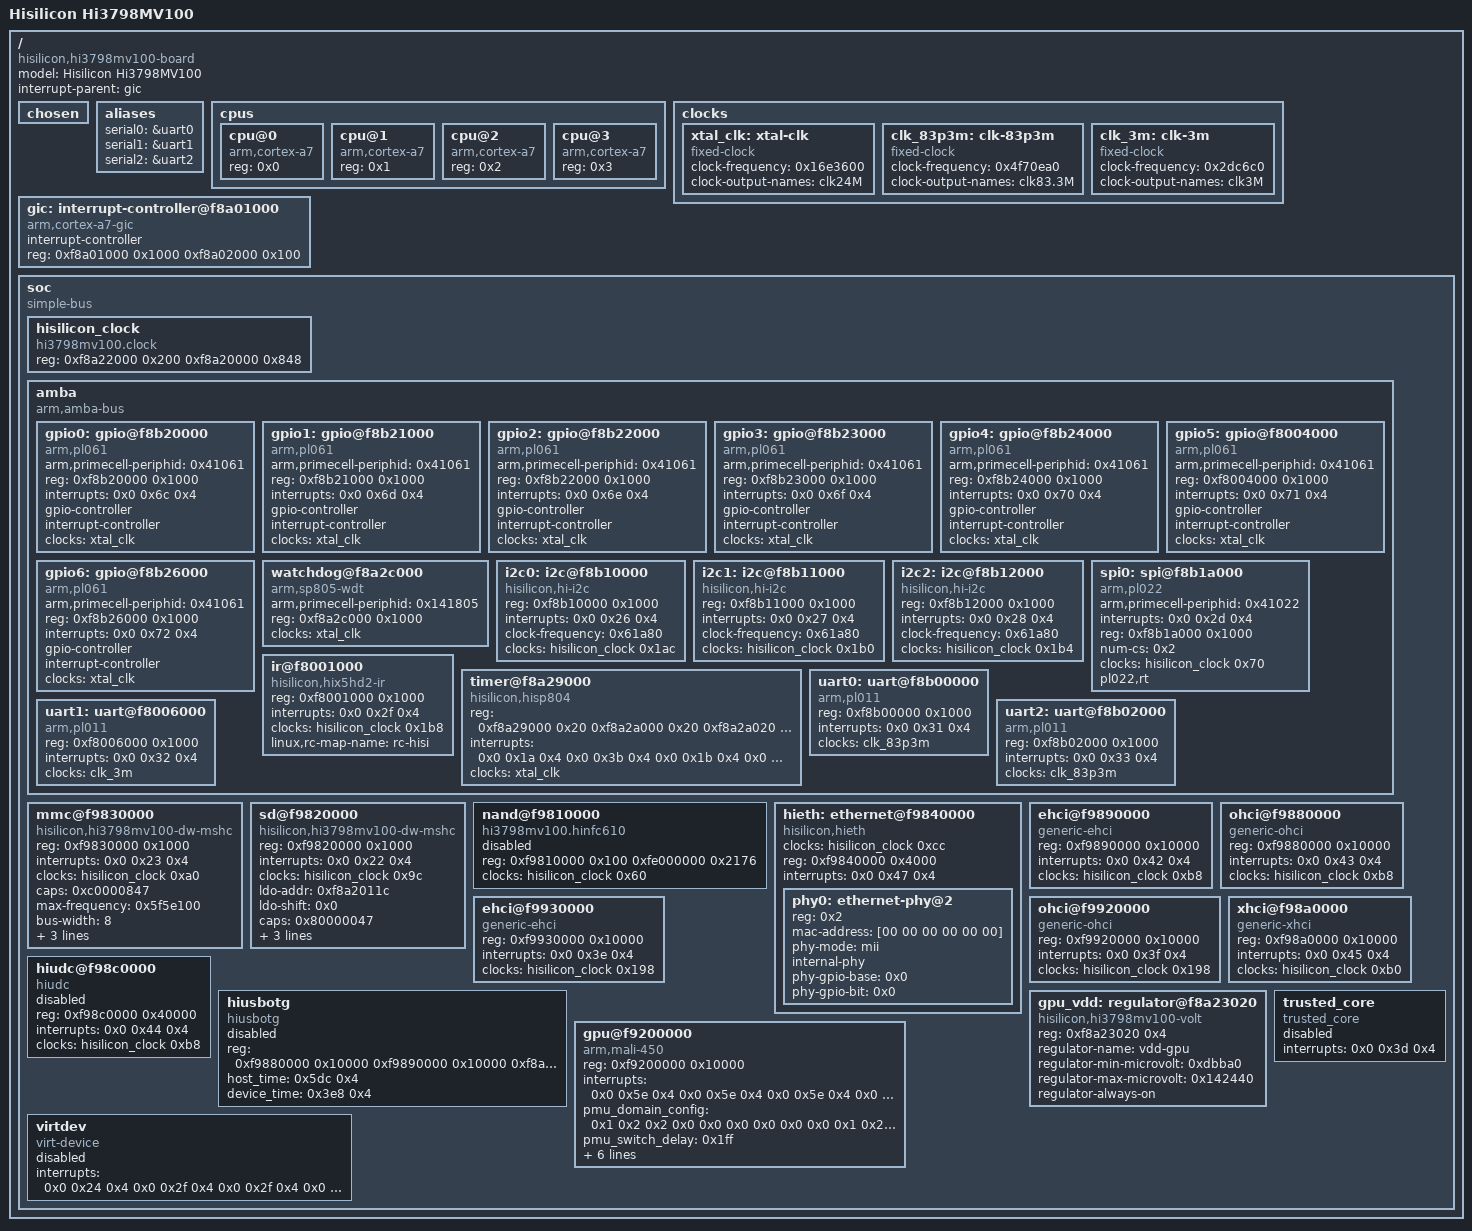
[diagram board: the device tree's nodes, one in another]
// SPDX-License-Identifier: GPL-2.0
/*
 * Device Tree for Hi3798MV100-based board
 *
 * Base: vendor DTB extracted from hi_kernel.bin (working vendor kernel)
 * All hardware addresses, IRQs, clock offsets and properties are taken
 * directly from the vendor DTB — these are confirmed correct for this board.
 *
 * Changes made for mainline kernel compilation:
 *  - Removed 0x prefix from all node @ unit addresses (dtc requirement)
 *  - Removed dots from node names (himciv200.MMC -> mmc, etc.)
 *  - Fixed soc ranges property
 *  - Replaced linux,phandle with phandle only
 *  - MMC/SD: added mainline compatible strings alongside vendor string
 *  - Clock controller: kept vendor compatible as fallback for raw offset clocks
 *  - Nodes with no mainline driver: trusted_core, virtdev, hiudc, hiusbotg
 *    are kept but marked status = "disabled" so they compile but don't probe
 *  - NAND: disabled, no mainline driver exists
 *  - chosen: emptied, U-Boot passes bootargs from its environment
 *  - Added #include for appended DTB support (no clock macros used —
 *    all clock references use the raw phandle+offset form from vendor DTB)
 */

/dts-v1/;

/ {
	model = "Hisilicon Hi3798MV100";
	compatible = "hisilicon,hi3798mv100-board", "hi3798mv100-series";
	#address-cells = <0x1>;
	#size-cells = <0x1>;
	interrupt-parent = <&gic>;

	/* Intentionally empty — U-Boot passes bootargs from its environment.
	 * CONFIG_ARM_ATAG_DTB_COMPAT_CMDLINE_FROM_BOOTLOADER=y handles this. */
	chosen {};

	aliases {
		serial0 = &uart0;
		serial1 = &uart1;
		serial2 = &uart2;
	};

	cpus {
		#address-cells = <0x1>;
		#size-cells = <0x0>;
		cpu@0 {
			device_type = "cpu";
			compatible = "arm,cortex-a7";
			reg = <0x0>;
		};
		cpu@1 {
			device_type = "cpu";
			compatible = "arm,cortex-a7";
			reg = <0x1>;
		};
		cpu@2 {
			device_type = "cpu";
			compatible = "arm,cortex-a7";
			reg = <0x2>;
		};
		cpu@3 {
			device_type = "cpu";
			compatible = "arm,cortex-a7";
			reg = <0x3>;
		};
	};

	/* Fixed clocks — values taken directly from vendor DTB */
	clocks {
		xtal_clk: xtal-clk {
			compatible = "fixed-clock";
			#clock-cells = <0x0>;
			clock-frequency = <0x16e3600>;    /* 24MHz */
			clock-output-names = "clk24M";
			phandle = <0x2>;
		};
		clk_83p3m: clk-83p3m {
			compatible = "fixed-clock";
			#clock-cells = <0x0>;
			clock-frequency = <0x4f70ea0>;    /* 83.3MHz */
			clock-output-names = "clk83.3M";
			phandle = <0x4>;
		};
		clk_3m: clk-3m {
			compatible = "fixed-clock";
			#clock-cells = <0x0>;
			clock-frequency = <0x2dc6c0>;     /* 3MHz */
			clock-output-names = "clk3M";
			phandle = <0x5>;
		};
	};

	/* GIC — addresses from vendor DTB */
	gic: interrupt-controller@f8a01000 {
		compatible = "arm,cortex-a7-gic";
		#interrupt-cells = <0x3>;
		#address-cells = <0x0>;
		interrupt-controller;
		reg = <0xf8a01000 0x1000 0xf8a02000 0x100>;
		phandle = <0x1>;
	};

	soc {
		#address-cells = <0x1>;
		#size-cells = <0x1>;
		compatible = "simple-bus";
		/* FIX: vendor had ranges = <0x0 0x0 0xffffffff> which is wrong.
		 * Empty ranges means 1:1 mapping of child to parent addresses. */
		ranges;

		/* Clock controller.
		 * Kept with vendor compatible "hi3798mv100.clock" because all
		 * peripheral clock references in this DTS use raw register offsets
		 * (<0x3 0xNN>) which only the vendor clock driver understands.
		 * The mainline hisilicon,hi3798mv100-crg driver uses index-based
		 * clock IDs from histb-clock.h which are different. Using the vendor
		 * compatible here means clocks work exactly as they did in the
		 * vendor kernel. If/when the mainline CRG driver gains MV100 support
		 * with matching clock IDs, this can be updated. */
		hisilicon_clock: hisilicon_clock {
			compatible = "hi3798mv100.clock";
			reg = <0xf8a22000 0x200 0xf8a20000 0x848>;
			#clock-cells = <0x1>;
			phandle = <0x3>;
		};

		amba {
			compatible = "arm,amba-bus";
			#address-cells = <0x1>;
			#size-cells = <0x1>;
			ranges;

			/* GPIO — no @ address in vendor DTB, added for mainline */
			gpio0: gpio@f8b20000 {
				compatible = "arm,pl061", "arm,primecell";
				arm,primecell-periphid = <0x41061>;
				reg = <0xf8b20000 0x1000>;
				interrupts = <0x0 0x6c 0x4>;
				gpio-controller;
				#gpio-cells = <0x2>;
				interrupt-controller;
				#interrupt-cells = <0x2>;
				clocks = <&xtal_clk>;
				clock-names = "apb_pclk";
			};
			gpio1: gpio@f8b21000 {
				compatible = "arm,pl061", "arm,primecell";
				arm,primecell-periphid = <0x41061>;
				reg = <0xf8b21000 0x1000>;
				interrupts = <0x0 0x6d 0x4>;
				gpio-controller;
				#gpio-cells = <0x2>;
				interrupt-controller;
				#interrupt-cells = <0x2>;
				clocks = <&xtal_clk>;
				clock-names = "apb_pclk";
			};
			gpio2: gpio@f8b22000 {
				compatible = "arm,pl061", "arm,primecell";
				arm,primecell-periphid = <0x41061>;
				reg = <0xf8b22000 0x1000>;
				interrupts = <0x0 0x6e 0x4>;
				gpio-controller;
				#gpio-cells = <0x2>;
				interrupt-controller;
				#interrupt-cells = <0x2>;
				clocks = <&xtal_clk>;
				clock-names = "apb_pclk";
			};
			gpio3: gpio@f8b23000 {
				compatible = "arm,pl061", "arm,primecell";
				arm,primecell-periphid = <0x41061>;
				reg = <0xf8b23000 0x1000>;
				interrupts = <0x0 0x6f 0x4>;
				gpio-controller;
				#gpio-cells = <0x2>;
				interrupt-controller;
				#interrupt-cells = <0x2>;
				clocks = <&xtal_clk>;
				clock-names = "apb_pclk";
			};
			gpio4: gpio@f8b24000 {
				compatible = "arm,pl061", "arm,primecell";
				arm,primecell-periphid = <0x41061>;
				reg = <0xf8b24000 0x1000>;
				interrupts = <0x0 0x70 0x4>;
				gpio-controller;
				#gpio-cells = <0x2>;
				interrupt-controller;
				#interrupt-cells = <0x2>;
				clocks = <&xtal_clk>;
				clock-names = "apb_pclk";
			};
			gpio5: gpio@f8004000 {
				compatible = "arm,pl061", "arm,primecell";
				arm,primecell-periphid = <0x41061>;
				reg = <0xf8004000 0x1000>;
				interrupts = <0x0 0x71 0x4>;
				gpio-controller;
				#gpio-cells = <0x2>;
				interrupt-controller;
				#interrupt-cells = <0x2>;
				clocks = <&xtal_clk>;
				clock-names = "apb_pclk";
			};
			gpio6: gpio@f8b26000 {
				compatible = "arm,pl061", "arm,primecell";
				arm,primecell-periphid = <0x41061>;
				reg = <0xf8b26000 0x1000>;
				interrupts = <0x0 0x72 0x4>;
				gpio-controller;
				#gpio-cells = <0x2>;
				interrupt-controller;
				#interrupt-cells = <0x2>;
				clocks = <&xtal_clk>;
				clock-names = "apb_pclk";
			};

			/* FIX: watchdog@0xf8a2c000 -> watchdog@f8a2c000 */
			watchdog@f8a2c000 {
				compatible = "arm,sp805-wdt", "arm,primecell";
				arm,primecell-periphid = <0x141805>;
				reg = <0xf8a2c000 0x1000>;
				clocks = <&xtal_clk>;
				clock-names = "apb_pclk";
			};

			/* FIX: i2c@0xf8b10000 -> i2c@f8b10000
			 * Clock: raw offset 0x1ac from vendor DTB, unchanged */
			i2c0: i2c@f8b10000 {
				compatible = "hisilicon,hi-i2c";
				reg = <0xf8b10000 0x1000>;
				interrupts = <0x0 0x26 0x4>;
				clock-frequency = <0x61a80>;
				clocks = <&hisilicon_clock 0x1ac>;
				clock-names = "apb_pclk";
				#address-cells = <0x1>;
				#size-cells = <0x0>;
			};
			i2c1: i2c@f8b11000 {
				compatible = "hisilicon,hi-i2c";
				reg = <0xf8b11000 0x1000>;
				interrupts = <0x0 0x27 0x4>;
				clock-frequency = <0x61a80>;
				clocks = <&hisilicon_clock 0x1b0>;
				clock-names = "apb_pclk";
				#address-cells = <0x1>;
				#size-cells = <0x0>;
			};
			i2c2: i2c@f8b12000 {
				compatible = "hisilicon,hi-i2c";
				reg = <0xf8b12000 0x1000>;
				interrupts = <0x0 0x28 0x4>;
				clock-frequency = <0x61a80>;
				clocks = <&hisilicon_clock 0x1b4>;
				clock-names = "apb_pclk";
				#address-cells = <0x1>;
				#size-cells = <0x0>;
			};

			/* FIX: spi@0xF8B1A000 -> spi@f8b1a000 */
			spi0: spi@f8b1a000 {
				compatible = "arm,pl022", "arm,primecell";
				arm,primecell-periphid = <0x41022>;
				interrupts = <0x0 0x2d 0x4>;
				reg = <0xf8b1a000 0x1000>;
				num-cs = <0x2>;
				#address-cells = <0x1>;
				#size-cells = <0x0>;
				clocks = <&hisilicon_clock 0x70>;
				clock-names = "apb_pclk";
				pl022,rt;
			};

			ir@f8001000 {
				compatible = "hisilicon,hix5hd2-ir";
				reg = <0xf8001000 0x1000>;
				interrupts = <0x0 0x2f 0x4>;
				clocks = <&hisilicon_clock 0x1b8>;
				linux,rc-map-name = "rc-hisi";
			};

			/* FIX: timer@hisp804 is not a valid unit address.
			 * Using first register base address as unit address. */
			timer@f8a29000 {
				compatible = "hisilicon,hisp804";
				reg = <0xf8a29000 0x20
				       0xf8a2a000 0x20
				       0xf8a2a020 0x20
				       0xf8a2b000 0x20
				       0xf8a2b020 0x20>;
				interrupts = <0x0 0x1a 0x4
				              0x0 0x3b 0x4
				              0x0 0x1b 0x4
				              0x0 0x3c 0x4>;
				clocks = <&xtal_clk>;
				clock-names = "apb_pclk";
			};

			/* UARTs — clocks taken directly from vendor DTB
			 * uart0 uses clk_83p3m (phandle 0x4)
			 * uart1 uses clk_3m (phandle 0x5)
			 * uart2 uses clk_83p3m (phandle 0x4) */
			uart0: uart@f8b00000 {
				compatible = "arm,pl011", "arm,primecell";
				reg = <0xf8b00000 0x1000>;
				interrupts = <0x0 0x31 0x4>;
				clocks = <&clk_83p3m>;
				clock-names = "apb_pclk";
			};
			uart1: uart@f8006000 {
				compatible = "arm,pl011", "arm,primecell";
				reg = <0xf8006000 0x1000>;
				interrupts = <0x0 0x32 0x4>;
				clocks = <&clk_3m>;
				clock-names = "apb_pclk";
			};
			uart2: uart@f8b02000 {
				compatible = "arm,pl011", "arm,primecell";
				reg = <0xf8b02000 0x1000>;
				interrupts = <0x0 0x33 0x4>;
				clocks = <&clk_83p3m>;
				clock-names = "apb_pclk";
			};
		}; /* amba */

		/* eMMC — FIX: himciv200.MMC@0xf9830000 -> mmc@f9830000
		 * Added mainline compatible strings before vendor string.
		 * Kernel tries each compatible in order; if mainline dw-mshc
		 * driver matches, it uses HISTB_MMC_* clocks. If not, the vendor
		 * himciv200 driver (if present) handles it via the last entry.
		 * Clock offset 0xa0 from vendor DTB preserved as fallback. */
		mmc@f9830000 {
			compatible = "hisilicon,hi3798mv100-dw-mshc",
			             "hisilicon,hi3798cv200-dw-mshc",
			             "snps,dw-mshc";
			reg = <0xf9830000 0x1000>;
			interrupts = <0x0 0x23 0x4>;
			clocks = <&hisilicon_clock 0xa0>;
			clock-names = "ciu";
			caps = <0xc0000847>;
			max-frequency = <0x5f5e100>;    /* 100MHz */
			bus-width = <8>;
			cap-mmc-highspeed;
			mmc-ddr-1_8v;
			non-removable;
		};

		/* SD card — FIX: himciv200.SD@0xf9820000 -> sd@f9820000 */
		sd@f9820000 {
			compatible = "hisilicon,hi3798mv100-dw-mshc",
			             "hisilicon,hi3798cv200-dw-mshc",
			             "snps,dw-mshc";
			reg = <0xf9820000 0x1000>;
			interrupts = <0x0 0x22 0x4>;
			clocks = <&hisilicon_clock 0x9c>;
			clock-names = "ciu";
			ldo-addr = <0xf8a2011c>;
			ldo-shift = <0x0>;
			caps = <0x80000047>;
			max-frequency = <0x5f5e100>;    /* 100MHz */
			bus-width = <4>;
			cap-sd-highspeed;
		};

		/* NAND — no mainline driver, disabled to prevent probe errors */
		nand@f9810000 {
			compatible = "hi3798mv100.hinfc610";
			reg = <0xf9810000 0x100
			       0xfe000000 0x2176>;
			clocks = <&hisilicon_clock 0x60>;
			clock-names = "clk";
			status = "disabled";
		};

		/* Ethernet — address taken from vendor DTB */
		hieth: ethernet@f9840000 {
			compatible = "hisilicon,hieth";
			clocks = <&hisilicon_clock 0xcc>;
			clock-names = "clk";
			reg = <0xf9840000 0x4000>;
			interrupts = <0x0 0x47 0x4>;
			#address-cells = <0x1>;
			#size-cells = <0x0>;

			phy0: ethernet-phy@2 {
				reg = <0x2>;
				mac-address = [00 00 00 00 00 00];
				phy-mode = "mii";
				internal-phy;
				phy-gpio-base = <0x0>;
				phy-gpio-bit = <0x0>;
				phandle = <0x6>;
			};
		};

		/* USB2 port 1 — FIX: ehci@0xf9890000 -> ehci@f9890000 */
		ehci@f9890000 {
			compatible = "generic-ehci";
			reg = <0xf9890000 0x10000>;
			interrupts = <0x0 0x42 0x4>;
			clocks = <&hisilicon_clock 0xb8>;
			clock-names = "clk";
		};
		ohci@f9880000 {
			compatible = "generic-ohci";
			reg = <0xf9880000 0x10000>;
			interrupts = <0x0 0x43 0x4>;
			clocks = <&hisilicon_clock 0xb8>;
			clock-names = "clk";
		};

		/* USB2 port 2 — FIX: ehci@0xf9930000 -> ehci@f9930000 */
		ehci@f9930000 {
			compatible = "generic-ehci";
			reg = <0xf9930000 0x10000>;
			interrupts = <0x0 0x3e 0x4>;
			clocks = <&hisilicon_clock 0x198>;
			clock-names = "clk";
		};
		ohci@f9920000 {
			compatible = "generic-ohci";
			reg = <0xf9920000 0x10000>;
			interrupts = <0x0 0x3f 0x4>;
			clocks = <&hisilicon_clock 0x198>;
			clock-names = "clk";
		};

		/* USB3 — FIX: xhci@0xf98a0000 -> xhci@f98a0000 */
		xhci@f98a0000 {
			compatible = "generic-xhci";
			reg = <0xf98a0000 0x10000>;
			interrupts = <0x0 0x45 0x4>;
			clocks = <&hisilicon_clock 0xb0>;
			clock-names = "clk";
		};

		/* USB device controller — vendor only, no mainline driver */
		hiudc@f98c0000 {
			compatible = "hiudc";
			reg = <0xf98c0000 0x40000>;
			interrupts = <0x0 0x44 0x4>;
			clocks = <&hisilicon_clock 0xb8>;
			clock-names = "clk";
			status = "disabled";
		};

		/* USB OTG — vendor only, no mainline driver */
		hiusbotg {
			compatible = "hiusbotg";
			reg = <0xf9880000 0x10000
			       0xf9890000 0x10000
			       0xf8a20120 0x4>;
			host_time = <0x5dc 0x4>;
			device_time = <0x3e8 0x4>;
			status = "disabled";
		};

		/* GPU voltage regulator — FIX: regulator@0xf8a23020 -> regulator@f8a23020 */
		gpu_vdd: regulator@f8a23020 {
			compatible = "hisilicon,hi3798mv100-volt";
			reg = <0xf8a23020 0x4>;
			reg-names = "base-address";
			regulator-name = "vdd-gpu";
			regulator-min-microvolt = <0xdbba0>;
			regulator-max-microvolt = <0x142440>;
			regulator-always-on;
			status = "okay";
			phandle = <0x7>;
		};

		/* GPU — FIX: gpu@0xf9200000 -> gpu@f9200000 */
		gpu@f9200000 {
			compatible = "arm,mali-450", "arm,mali-utgard";
			reg = <0xf9200000 0x10000>;
			interrupts = <0x0 0x5e 0x4
			              0x0 0x5e 0x4
			              0x0 0x5e 0x4
			              0x0 0x5e 0x4
			              0x0 0x5e 0x4
			              0x0 0x5e 0x4
			              0x0 0x5e 0x4
			              0x0 0x5e 0x4>;
			interrupt-names = "IRQGP", "IRQGPMMU", "IRQPP0", "IRQPPMMU0",
			                  "IRQPP1", "IRQPPMMU1", "IRQPMU", "IRQPP";
			pmu_domain_config = <0x1 0x2 0x2 0x0 0x0 0x0
			                     0x0 0x0 0x0 0x1 0x2 0x0>;
			pmu_switch_delay = <0x1ff>;
			#cooling-cells = <0x2>;
			clocks = <&hisilicon_clock 0x124>;
			clock-names = "clk_mali";
			mali-supply = <&gpu_vdd>;
			operating-points-tt = <0x8f0d180 0x0
			                       0xbebc200 0x0
			                       0xee6b280 0x0
			                       0x11e1a300 0x0
			                       0x14997000 0x0
			                       0x17d78400 0x0
			                       0x19bfcc00 0x0
			                       0x1dcd6500 0x0>;
			cooling-min-state = <0x0>;
			cooling-max-state = <0x7>;
			status = "okay";
		};

		/* Trusted core — vendor TEE, no mainline driver, removed interrupt
		 * conflict with hiudc. Kept as disabled for reference. */
		trusted_core {
			compatible = "trusted_core";
			interrupts = <0x0 0x3d 0x4>;
			status = "disabled";
		};

		/* Virtual device interrupt aggregator — vendor only */
		virtdev {
			compatible = "virt-device";
			interrupts = <0x0 0x24 0x4
			              0x0 0x2f 0x4
			              0x0 0x2f 0x4
			              0x0 0x30 0x4
			              0x0 0x30 0x4
			              0x0 0x4b 0x4
			              0x0 0x52 0x4
			              0x0 0x54 0x4
			              0x0 0x58 0x4
			              0x0 0x5a 0x4
			              0x0 0x5b 0x4
			              0x0 0x5d 0x4
			              0x0 0x5e 0x4
			              0x0 0x5f 0x4
			              0x0 0x60 0x4
			              0x0 0x61 0x4
			              0x0 0x65 0x4
			              0x0 0x66 0x4
			              0x0 0x68 0x4
			              0x0 0x69 0x4
			              0x0 0x6a 0x4
			              0x0 0x7e 0x4>;
			interrupt-names = "sci0", "ir_std", "ir_s2",
			                  "keyled_ct1642", "keyled_std",
			                  "multicipher", "dmx", "aiao", "hdmi",
			                  "vdp", "tde", "vpss0", "gpu",
			                  "vdec_vdh", "png", "jpeg", "venc",
			                  "jpge", "vdec_scd", "vdec_vdh_safe",
			                  "vdec_scd_safe", "cipher";
			status = "disabled";
		};

	}; /* soc */
};
